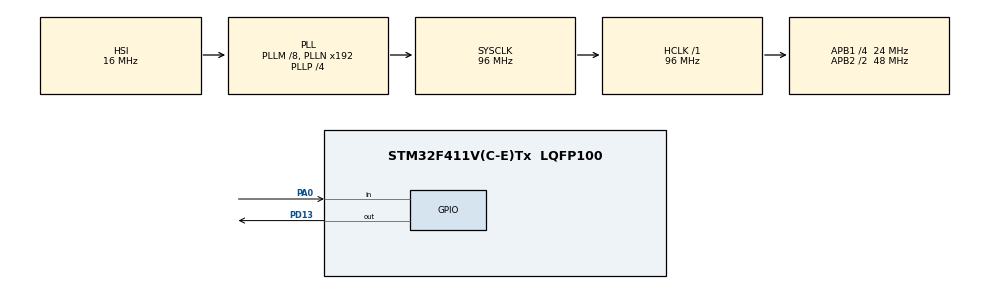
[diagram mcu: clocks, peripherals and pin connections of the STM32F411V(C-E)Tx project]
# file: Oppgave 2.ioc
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Mcu.Family=STM32F4
Mcu.Name=STM32F411V(C-E)Tx
Mcu.Package=LQFP100
NVIC.PriorityGroup=NVIC_PRIORITYGROUP_0
PA0-WKUP.Signal=GPIO_Input
PD13.Signal=GPIO_Output
ProjectManager.HeapSize=0x200
ProjectManager.StackSize=0x400
ProjectManager.TargetToolchain=STM32CubeIDE
RCC.48MHZClocksFreq_Value=48000000
RCC.AHBFreq_Value=96000000
RCC.APB1CLKDivider=RCC_HCLK_DIV4
RCC.APB1Freq_Value=24000000
RCC.APB1TimFreq_Value=48000000
RCC.APB2CLKDivider=RCC_HCLK_DIV2
RCC.APB2Freq_Value=48000000
RCC.APB2TimFreq_Value=96000000
RCC.CortexFreq_Value=96000000
RCC.HCLKFreq_Value=96000000
RCC.HSE_VALUE=8000000
RCC.HSI_VALUE=16000000
RCC.LSE_VALUE=32768
RCC.PLLI2SM=5
RCC.PLLI2SN=200
RCC.PLLM=8
RCC.PLLP=RCC_PLLP_DIV4
RCC.PLLQ=8
RCC.SYSCLKFreq_VALUE=96000000
RCC.SYSCLKSource=RCC_SYSCLKSOURCE_PLLCLK
RCC.VCOOutputFreq_Value=384000000
board=STM32F411E-DISCO

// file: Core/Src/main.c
/* USER CODE BEGIN Header */
/**
  ******************************************************************************
  * @file           : main.c
  * @brief          : Main program body
  ******************************************************************************
  * @attention
  *
  * Copyright (c) 2024 STMicroelectronics.
  * All rights reserved.
  *
  * This software is licensed under terms that can be found in the LICENSE file
  * in the root directory of this software component.
  * If no LICENSE file comes with this software, it is provided AS-IS.
  *
  ******************************************************************************
  */
/* USER CODE END Header */
#include "main.h"

/* USER CODE BEGIN PV */
// DEL 2&3
GPIO_TypeDef* D23_GPIO_Port = GPIOD; /* GPIO port for toggling LED from "Del 2&3" */

// DEL 2
uint16_t D2_GPIO_Pin = GPIO_PIN_12; /* GPIO pin for toggling LED from "Del 2" */
int D2_delay = 1000; /* Delay for "Del 2" */

// DEL 3
int D3_GPIO_PIN = 12; /* GPIO pin for toggling LED from "Del 3" */
int D3_delay = 500; /* Delay for "Del 3" */

// DEL 4
GPIO_TypeDef* D4_orLED_Port = GPIOD; /* GPIO port for Orange LED for "Del 4" */
GPIO_TypeDef* D4_B1_Port = GPIOA; /* GPIO port for Button 1 for "Del 4" */
int D4_orLED_Pin = 13; /* GPIO pin for Orange LED for "Del 4" */
int D4_B1_Pin = 0; /* GPIO pin for Button 1 for "Del 4" */
/* USER CODE END PV */

void SystemClock_Config(void);
static void MX_GPIO_Init(void);

int main(void)
{

  /* MCU Configuration--------------------------------------------------------*/

  /* Reset of all peripherals, Initializes the Flash interface and the Systick. */
  HAL_Init();

  /* Configure the system clock */
  SystemClock_Config();

  /* Initialize all configured peripherals */
  MX_GPIO_Init();

  /* Infinite loop */
  /* USER CODE BEGIN WHILE */
  while (1)
  {
/* DEL 2 - BLINK GREEN LED WITH 1sec INTERVAL USING PRE-DEFINED FUNCTION*/

	  /* Toggle pin using HAL Driver - on if off (pin state 1/high if 0/low), and vice versa
	   * 	OBS - Set LED pin mode to Output in .ioc */
	  // HAL_GPIO_TogglePin(D23_GPIO_Port, D2_GPIO_Pin);

	  /* Delay of x number of milliseconds */
	  // HAL_Delay(D2_delay);

/* DEL 3 - BLINK GREEN LED USING BSRR (Bit Set/Reset Register)*/

	  /** Turn LED on by setting the pin to high ->
	   * 	Setting bits 0 to 15 will set the corresponding pin high (1)
	   * 	For 'GPIO_PIN_12', write '1 << 12' to BSRR
	   * 	OBS - Set LED pin mode to Output in .ioc */
	  //D23_GPIO_Port->BSRR = (1 << D3_GPIO_PIN);

	  //HAL_Delay(D3_delay); // 500ms delay

	  /** Turn LED off by resetting the pin ->
	   * 	Setting bits 16 to 31 will set the corresponding pin high (0)
	   * 	For 'GPIO_PIN_12', this would be bit 12 + 16 = 28, so write '1 << (12 + 16)' to BSRR */
	  //D23_GPIO_Port->BSRR = (1 << (D3_GPIO_PIN + 16));

	  //HAL_Delay(D3_delay); // 500ms delay

/* DEL 4 - BLINK ORANGE LED USING BUTTON*/

	  /** Use B1 to turn orange LED on/off
	   * 	When button is pressed, turn light on
	   * 	When button isn't pressed, turn light off
	   * 	OBS - Set LED pin mode to Output and B1 pin mode to Input in .ioc */
//	  if (D4_B1_Port->IDR & (1 << D4_B1_Pin)){
//		  D4_orLED_Port->BSRR = (1 << D4_orLED_Pin);
//	  }
//	  else {
//		  D4_orLED_Port->BSRR = (1 << (D4_orLED_Pin + 16));
//	  }
    /* USER CODE END WHILE */

  }
}

void SystemClock_Config(void)
{
  RCC_OscInitTypeDef RCC_OscInitStruct = {0};
  RCC_ClkInitTypeDef RCC_ClkInitStruct = {0};

  /** Configure the main internal regulator output voltage
  */
  __HAL_RCC_PWR_CLK_ENABLE();
  __HAL_PWR_VOLTAGESCALING_CONFIG(PWR_REGULATOR_VOLTAGE_SCALE1);

  /** Initializes the RCC Oscillators according to the specified parameters
  * in the RCC_OscInitTypeDef structure.
  */
  RCC_OscInitStruct.OscillatorType = RCC_OSCILLATORTYPE_HSI;
  RCC_OscInitStruct.HSIState = RCC_HSI_ON;
  RCC_OscInitStruct.HSICalibrationValue = RCC_HSICALIBRATION_DEFAULT;
  RCC_OscInitStruct.PLL.PLLState = RCC_PLL_ON;
  RCC_OscInitStruct.PLL.PLLSource = RCC_PLLSOURCE_HSI;
  RCC_OscInitStruct.PLL.PLLM = 8;
  RCC_OscInitStruct.PLL.PLLN = 192;
  RCC_OscInitStruct.PLL.PLLP = RCC_PLLP_DIV4;
  RCC_OscInitStruct.PLL.PLLQ = 8;
  if (HAL_RCC_OscConfig(&RCC_OscInitStruct) != HAL_OK)
  {
    Error_Handler();
  }

  /** Initializes the CPU, AHB and APB buses clocks
  */
  RCC_ClkInitStruct.ClockType = RCC_CLOCKTYPE_HCLK|RCC_CLOCKTYPE_SYSCLK
                              |RCC_CLOCKTYPE_PCLK1|RCC_CLOCKTYPE_PCLK2;
  RCC_ClkInitStruct.SYSCLKSource = RCC_SYSCLKSOURCE_PLLCLK;
  RCC_ClkInitStruct.AHBCLKDivider = RCC_SYSCLK_DIV1;
  RCC_ClkInitStruct.APB1CLKDivider = RCC_HCLK_DIV4;
  RCC_ClkInitStruct.APB2CLKDivider = RCC_HCLK_DIV2;

  if (HAL_RCC_ClockConfig(&RCC_ClkInitStruct, FLASH_LATENCY_3) != HAL_OK)
  {
    Error_Handler();
  }
}

static void MX_GPIO_Init(void)
{
  GPIO_InitTypeDef GPIO_InitStruct = {0};

  /* GPIO Ports Clock Enable */
  __HAL_RCC_GPIOA_CLK_ENABLE();
  __HAL_RCC_GPIOD_CLK_ENABLE();

  /*Configure GPIO pin Output Level */
  HAL_GPIO_WritePin(GPIOD, GPIO_PIN_13, GPIO_PIN_RESET);

  /*Configure GPIO pin : PA0 */
  GPIO_InitStruct.Pin = GPIO_PIN_0;
  GPIO_InitStruct.Mode = GPIO_MODE_INPUT;
  GPIO_InitStruct.Pull = GPIO_NOPULL;
  HAL_GPIO_Init(GPIOA, &GPIO_InitStruct);

  /*Configure GPIO pin : PD13 */
  GPIO_InitStruct.Pin = GPIO_PIN_13;
  GPIO_InitStruct.Mode = GPIO_MODE_OUTPUT_PP;
  GPIO_InitStruct.Pull = GPIO_NOPULL;
  GPIO_InitStruct.Speed = GPIO_SPEED_FREQ_LOW;
  HAL_GPIO_Init(GPIOD, &GPIO_InitStruct);

}

void Error_Handler(void)
{
  __disable_irq();
  while (1)
  {
  }
}
